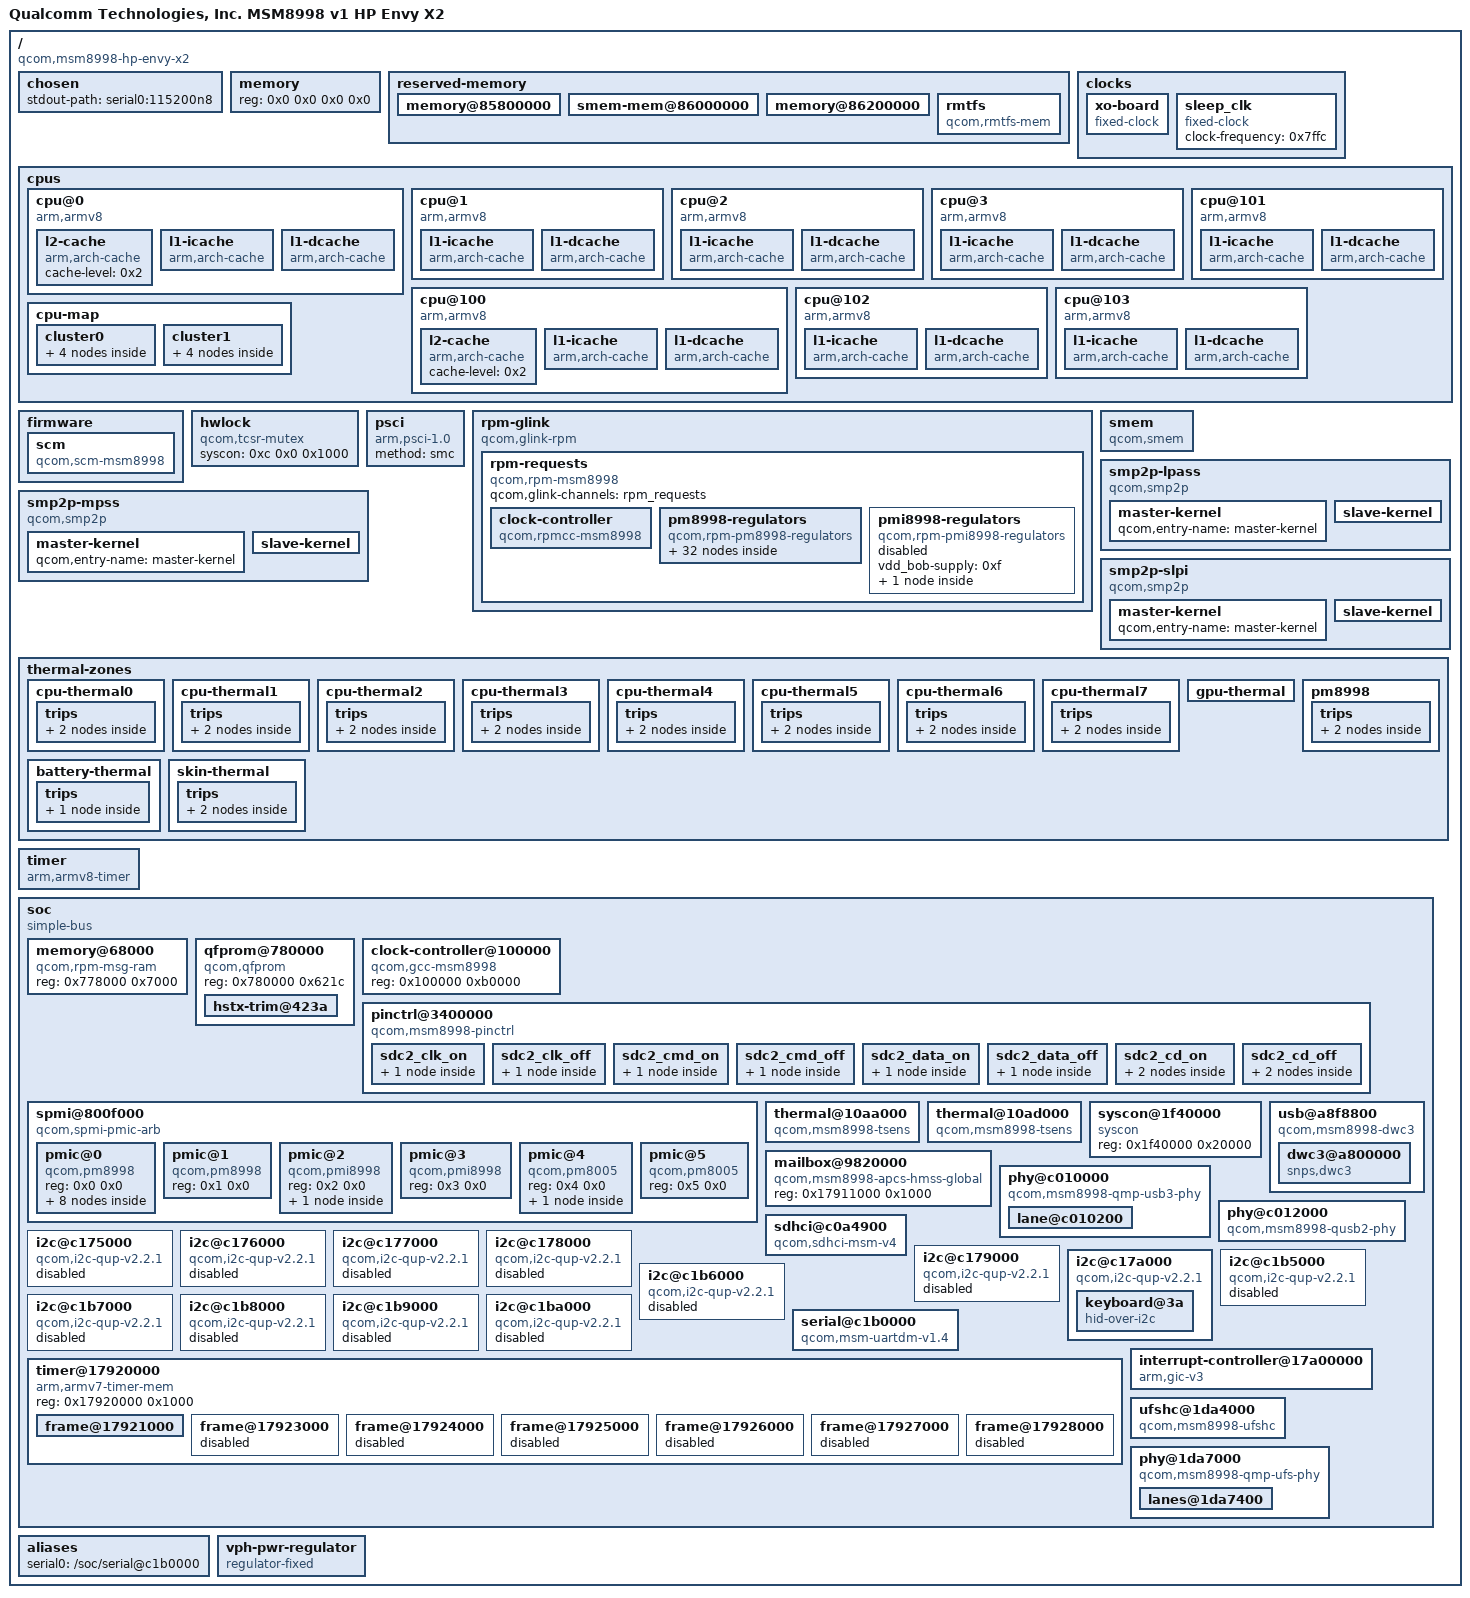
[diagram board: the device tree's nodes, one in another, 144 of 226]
/dts-v1/;

/ {
	interrupt-parent = <0x1>;
	qcom,msm-id = <0x124 0x0>;
	#address-cells = <0x2>;
	#size-cells = <0x2>;
	model = "Qualcomm Technologies, Inc. MSM8998 v1 HP Envy X2";
	compatible = "qcom,msm8998-hp-envy-x2";
	qcom,board-id = <0x8 0x0>;

	chosen {
		stdout-path = "serial0:115200n8";
	};

	memory {
		device_type = "memory";
		reg = <0x0 0x0 0x0 0x0>;
	};

	reserved-memory {
		#address-cells = <0x2>;
		#size-cells = <0x2>;
		ranges;

		memory@85800000 {
			reg = <0x0 0x85800000 0x0 0x800000>;
			no-map;
		};

		smem-mem@86000000 {
			reg = <0x0 0x86000000 0x0 0x200000>;
			no-map;
			phandle = <0x14>;
		};

		memory@86200000 {
			reg = <0x0 0x86200000 0x0 0x2600000>;
			no-map;
		};

		rmtfs {
			compatible = "qcom,rmtfs-mem";
			size = <0x0 0x200000>;
			alloc-ranges = <0x0 0xa0000000 0x0 0x2000000>;
			no-map;
			qcom,client-id = <0x1>;
			qcom,vmid = <0xf>;
		};
	};

	clocks {

		xo-board {
			compatible = "fixed-clock";
			#clock-cells = <0x0>;
			clock-frequency = <0x124f800>;
			clock-output-names = "xo_board";
			phandle = <0x21>;
		};

		sleep_clk {
			compatible = "fixed-clock";
			#clock-cells = <0x0>;
			clock-frequency = <0x7ffc>;
		};
	};

	cpus {
		#address-cells = <0x2>;
		#size-cells = <0x0>;

		cpu@0 {
			device_type = "cpu";
			compatible = "arm,armv8";
			reg = <0x0 0x0>;
			enable-method = "psci";
			efficiency = <0x400>;
			next-level-cache = <0x2>;
			phandle = <0x4>;

			l2-cache {
				compatible = "arm,arch-cache";
				cache-level = <0x2>;
				phandle = <0x2>;
			};

			l1-icache {
				compatible = "arm,arch-cache";
			};

			l1-dcache {
				compatible = "arm,arch-cache";
			};
		};

		cpu@1 {
			device_type = "cpu";
			compatible = "arm,armv8";
			reg = <0x0 0x1>;
			enable-method = "psci";
			efficiency = <0x400>;
			next-level-cache = <0x2>;
			phandle = <0x5>;

			l1-icache {
				compatible = "arm,arch-cache";
			};

			l1-dcache {
				compatible = "arm,arch-cache";
			};
		};

		cpu@2 {
			device_type = "cpu";
			compatible = "arm,armv8";
			reg = <0x0 0x2>;
			enable-method = "psci";
			efficiency = <0x400>;
			next-level-cache = <0x2>;
			phandle = <0x6>;

			l1-icache {
				compatible = "arm,arch-cache";
			};

			l1-dcache {
				compatible = "arm,arch-cache";
			};
		};

		cpu@3 {
			device_type = "cpu";
			compatible = "arm,armv8";
			reg = <0x0 0x3>;
			enable-method = "psci";
			efficiency = <0x400>;
			next-level-cache = <0x2>;
			phandle = <0x7>;

			l1-icache {
				compatible = "arm,arch-cache";
			};

			l1-dcache {
				compatible = "arm,arch-cache";
			};
		};

		cpu@100 {
			device_type = "cpu";
			compatible = "arm,armv8";
			reg = <0x0 0x100>;
			enable-method = "psci";
			efficiency = <0x600>;
			next-level-cache = <0x3>;
			phandle = <0x8>;

			l2-cache {
				compatible = "arm,arch-cache";
				cache-level = <0x2>;
				phandle = <0x3>;
			};

			l1-icache {
				compatible = "arm,arch-cache";
			};

			l1-dcache {
				compatible = "arm,arch-cache";
			};
		};

		cpu@101 {
			device_type = "cpu";
			compatible = "arm,armv8";
			reg = <0x0 0x101>;
			enable-method = "psci";
			efficiency = <0x600>;
			next-level-cache = <0x3>;
			phandle = <0x9>;

			l1-icache {
				compatible = "arm,arch-cache";
			};

			l1-dcache {
				compatible = "arm,arch-cache";
			};
		};

		cpu@102 {
			device_type = "cpu";
			compatible = "arm,armv8";
			reg = <0x0 0x102>;
			enable-method = "psci";
			efficiency = <0x600>;
			next-level-cache = <0x3>;
			phandle = <0xa>;

			l1-icache {
				compatible = "arm,arch-cache";
			};

			l1-dcache {
				compatible = "arm,arch-cache";
			};
		};

		cpu@103 {
			device_type = "cpu";
			compatible = "arm,armv8";
			reg = <0x0 0x103>;
			enable-method = "psci";
			efficiency = <0x600>;
			next-level-cache = <0x3>;
			phandle = <0xb>;

			l1-icache {
				compatible = "arm,arch-cache";
			};

			l1-dcache {
				compatible = "arm,arch-cache";
			};
		};

		cpu-map {

			cluster0 {

				core0 {
					cpu = <0x4>;
				};

				core1 {
					cpu = <0x5>;
				};

				core2 {
					cpu = <0x6>;
				};

				core3 {
					cpu = <0x7>;
				};
			};

			cluster1 {

				core0 {
					cpu = <0x8>;
				};

				core1 {
					cpu = <0x9>;
				};

				core2 {
					cpu = <0xa>;
				};

				core3 {
					cpu = <0xb>;
				};
			};
		};
	};

	firmware {

		scm {
			compatible = "qcom,scm-msm8998", "qcom,scm";
		};
	};

	hwlock {
		compatible = "qcom,tcsr-mutex";
		syscon = <0xc 0x0 0x1000>;
		#hwlock-cells = <0x1>;
		phandle = <0x15>;
	};

	psci {
		compatible = "arm,psci-1.0";
		method = "smc";
	};

	rpm-glink {
		compatible = "qcom,glink-rpm";
		interrupts = <0x0 0xa8 0x1>;
		qcom,rpm-msg-ram = <0xd>;
		mboxes = <0xe 0x0>;

		rpm-requests {
			compatible = "qcom,rpm-msm8998";
			qcom,glink-channels = "rpm_requests";

			clock-controller {
				compatible = "qcom,rpmcc-msm8998", "qcom,rpmcc";
				#clock-cells = <0x1>;
				phandle = <0x2e>;
			};

			pm8998-regulators {
				compatible = "qcom,rpm-pm8998-regulators";
				vdd_s1-supply = <0xf>;
				vdd_s2-supply = <0xf>;
				vdd_s3-supply = <0xf>;
				vdd_s4-supply = <0xf>;
				vdd_s5-supply = <0xf>;
				vdd_s6-supply = <0xf>;
				vdd_s7-supply = <0xf>;
				vdd_s8-supply = <0xf>;
				vdd_s9-supply = <0xf>;
				vdd_s10-supply = <0xf>;
				vdd_s11-supply = <0xf>;
				vdd_s12-supply = <0xf>;
				vdd_s13-supply = <0xf>;
				vdd_l1_l27-supply = <0x10>;
				vdd_l2_l8_l17-supply = <0x11>;
				vdd_l3_l11-supply = <0x10>;
				vdd_l4_l5-supply = <0x10>;
				vdd_l6-supply = <0x12>;
				vdd_l7_l12_l14_l15-supply = <0x12>;
				vdd_l9-supply = <0xf>;
				vdd_l10_l23_l25-supply = <0xf>;
				vdd_l13_l19_l21-supply = <0xf>;
				vdd_l16_l28-supply = <0xf>;
				vdd_l18_l22-supply = <0xf>;
				vdd_l20_l24-supply = <0xf>;
				vdd_l26-supply = <0x11>;
				vdd_lvs1_lvs2-supply = <0x13>;
				status = "okay";

				s3 {
					regulator-min-microvolt = <0x14a140>;
					regulator-max-microvolt = <0x14a140>;
					phandle = <0x11>;
				};

				s4 {
					regulator-min-microvolt = <0x1b7740>;
					regulator-max-microvolt = <0x1b7740>;
					regulator-allow-set-load;
					phandle = <0x13>;
				};

				s5 {
					regulator-min-microvolt = <0x1d0d80>;
					regulator-max-microvolt = <0x1f20c0>;
					phandle = <0x12>;
				};

				s7 {
					regulator-min-microvolt = <0xdbba0>;
					regulator-max-microvolt = <0xfafa0>;
					phandle = <0x10>;
				};

				l1 {
					regulator-min-microvolt = <0xd6d80>;
					regulator-max-microvolt = <0xd6d80>;
					phandle = <0x1c>;
				};

				l2 {
					regulator-min-microvolt = <0x124f80>;
					regulator-max-microvolt = <0x124f80>;
					phandle = <0x1d>;
				};

				l3 {
					regulator-min-microvolt = <0xf4240>;
					regulator-max-microvolt = <0xf4240>;
				};

				l5 {
					regulator-min-microvolt = <0xc3500>;
					regulator-max-microvolt = <0xc3500>;
				};

				l6 {
					regulator-min-microvolt = <0x1b9680>;
					regulator-max-microvolt = <0x1b9680>;
				};

				l7 {
					regulator-min-microvolt = <0x1b7740>;
					regulator-max-microvolt = <0x1b7740>;
				};

				l8 {
					regulator-min-microvolt = <0x124f80>;
					regulator-max-microvolt = <0x124f80>;
				};

				l9 {
					regulator-min-microvolt = <0x1b9680>;
					regulator-max-microvolt = <0x2d2a80>;
				};

				l10 {
					regulator-min-microvolt = <0x1b9680>;
					regulator-max-microvolt = <0x2d2a80>;
				};

				l11 {
					regulator-min-microvolt = <0xf4240>;
					regulator-max-microvolt = <0xf4240>;
				};

				l12 {
					regulator-min-microvolt = <0x1b7740>;
					regulator-max-microvolt = <0x1b7740>;
					phandle = <0x1f>;
				};

				l13 {
					regulator-min-microvolt = <0x1b9680>;
					regulator-max-microvolt = <0x2d2a80>;
					phandle = <0x24>;
				};

				l14 {
					regulator-min-microvolt = <0x1cafc0>;
					regulator-max-microvolt = <0x1cafc0>;
				};

				l15 {
					regulator-min-microvolt = <0x1b7740>;
					regulator-max-microvolt = <0x1b7740>;
				};

				l16 {
					regulator-min-microvolt = <0x294280>;
					regulator-max-microvolt = <0x294280>;
				};

				l17 {
					regulator-min-microvolt = <0x13e5c0>;
					regulator-max-microvolt = <0x13e5c0>;
				};

				l18 {
					regulator-min-microvolt = <0x294280>;
					regulator-max-microvolt = <0x294280>;
				};

				l19 {
					regulator-min-microvolt = <0x2de600>;
					regulator-max-microvolt = <0x2de600>;
				};

				l20 {
					regulator-min-microvolt = <0x2d2a80>;
					regulator-max-microvolt = <0x2d2a80>;
					regulator-allow-set-load;
					phandle = <0x2f>;
				};

				l21 {
					regulator-min-microvolt = <0x2d2a80>;
					regulator-max-microvolt = <0x2d2a80>;
					regulator-allow-set-load;
					regulator-system-load = <0xc3500>;
					phandle = <0x23>;
				};

				l22 {
					regulator-min-microvolt = <0x2bb380>;
					regulator-max-microvolt = <0x2bb380>;
				};

				l23 {
					regulator-min-microvolt = <0x328980>;
					regulator-max-microvolt = <0x328980>;
				};

				l24 {
					regulator-min-microvolt = <0x2f1e80>;
					regulator-max-microvolt = <0x2f1e80>;
					phandle = <0x20>;
				};

				l25 {
					regulator-min-microvolt = <0x2f5d00>;
					regulator-max-microvolt = <0x328980>;
				};

				l26 {
					regulator-min-microvolt = <0x124f80>;
					regulator-max-microvolt = <0x124f80>;
					regulator-allow-set-load;
					phandle = <0x30>;
				};

				l28 {
					regulator-min-microvolt = <0x2de600>;
					regulator-max-microvolt = <0x2de600>;
				};

				lvs1 {
					regulator-min-microvolt = <0x1b7740>;
					regulator-max-microvolt = <0x1b7740>;
				};

				lvs2 {
					regulator-min-microvolt = <0x1b7740>;
					regulator-max-microvolt = <0x1b7740>;
				};
			};

			pmi8998-regulators {
				compatible = "qcom,rpm-pmi8998-regulators";
				vdd_bob-supply = <0xf>;
				status = "disabled";

				bob {
					regulator-min-microvolt = <0x328980>;
					regulator-max-microvolt = <0x36ee80>;
				};
			};
		};
	};

	smem {
		compatible = "qcom,smem";
		memory-region = <0x14>;
		hwlocks = <0x15 0x3>;
	};

	smp2p-lpass {
		compatible = "qcom,smp2p";
		qcom,smem = <0x1bb 0x1ad>;
		interrupts = <0x0 0x9e 0x1>;
		mboxes = <0xe 0xa>;
		qcom,local-pid = <0x0>;
		qcom,remote-pid = <0x2>;

		master-kernel {
			qcom,entry-name = "master-kernel";
			#qcom,smem-state-cells = <0x1>;
		};

		slave-kernel {
			qcom,entry-name = "slave-kernel";
			interrupt-controller;
			#interrupt-cells = <0x2>;
		};
	};

	smp2p-mpss {
		compatible = "qcom,smp2p";
		qcom,smem = <0x1b3 0x1ac>;
		interrupts = <0x0 0x1c3 0x1>;
		mboxes = <0xe 0xe>;
		qcom,local-pid = <0x0>;
		qcom,remote-pid = <0x1>;

		master-kernel {
			qcom,entry-name = "master-kernel";
			#qcom,smem-state-cells = <0x1>;
		};

		slave-kernel {
			qcom,entry-name = "slave-kernel";
			interrupt-controller;
			#interrupt-cells = <0x2>;
		};
	};

	smp2p-slpi {
		compatible = "qcom,smp2p";
		qcom,smem = <0x1e1 0x1ae>;
		interrupts = <0x0 0xb2 0x1>;
		mboxes = <0xe 0x1a>;
		qcom,local-pid = <0x0>;
		qcom,remote-pid = <0x3>;

		master-kernel {
			qcom,entry-name = "master-kernel";
			#qcom,smem-state-cells = <0x1>;
		};

		slave-kernel {
			qcom,entry-name = "slave-kernel";
			interrupt-controller;
			#interrupt-cells = <0x2>;
		};
	};

	thermal-zones {

		cpu-thermal0 {
			polling-delay-passive = <0xfa>;
			polling-delay = <0x3e8>;
			thermal-sensors = <0x16 0x6>;

			trips {

				trip0 {
					temperature = <0x124f8>;
					hysteresis = <0x7d0>;
					type = "passive";
				};

				trip1 {
					temperature = <0x1adb0>;
					hysteresis = <0x7d0>;
					type = "critical";
				};
			};
		};

		cpu-thermal1 {
			polling-delay-passive = <0xfa>;
			polling-delay = <0x3e8>;
			thermal-sensors = <0x16 0x7>;

			trips {

				trip0 {
					temperature = <0x124f8>;
					hysteresis = <0x7d0>;
					type = "passive";
				};

				trip1 {
					temperature = <0x1adb0>;
					hysteresis = <0x7d0>;
					type = "critical";
				};
			};
		};

		cpu-thermal2 {
			polling-delay-passive = <0xfa>;
			polling-delay = <0x3e8>;
			thermal-sensors = <0x16 0x8>;

			trips {

				trip0 {
					temperature = <0x124f8>;
					hysteresis = <0x7d0>;
					type = "passive";
				};

				trip1 {
					temperature = <0x1adb0>;
					hysteresis = <0x7d0>;
					type = "critical";
				};
			};
		};

		cpu-thermal3 {
			polling-delay-passive = <0xfa>;
			polling-delay = <0x3e8>;
			thermal-sensors = <0x16 0x9>;

			trips {

				trip0 {
					temperature = <0x124f8>;
					hysteresis = <0x7d0>;
					type = "passive";
				};

				trip1 {
					temperature = <0x1adb0>;
					hysteresis = <0x7d0>;
					type = "critical";
				};
			};
		};

		cpu-thermal4 {
			polling-delay-passive = <0xfa>;
			polling-delay = <0x3e8>;
			thermal-sensors = <0x16 0xa>;

			trips {

				trip0 {
					temperature = <0x124f8>;
					hysteresis = <0x7d0>;
					type = "passive";
				};

				trip1 {
					temperature = <0x1adb0>;
					hysteresis = <0x7d0>;
					type = "critical";
				};
			};
		};

		cpu-thermal5 {
			polling-delay-passive = <0xfa>;
			polling-delay = <0x3e8>;
			thermal-sensors = <0x16 0xb>;

			trips {

				trip0 {
					temperature = <0x124f8>;
					hysteresis = <0x7d0>;
					type = "passive";
				};

				trip1 {
					temperature = <0x1adb0>;
					hysteresis = <0x7d0>;
					type = "critical";
				};
			};
		};

		cpu-thermal6 {
			polling-delay-passive = <0xfa>;
			polling-delay = <0x3e8>;
			thermal-sensors = <0x17 0x0>;

			trips {

				trip0 {
					temperature = <0x124f8>;
					hysteresis = <0x7d0>;
					type = "passive";
				};

				trip1 {
					temperature = <0x1adb0>;
					hysteresis = <0x7d0>;
					type = "critical";
				};
			};
		};

		cpu-thermal7 {
			polling-delay-passive = <0xfa>;
			polling-delay = <0x3e8>;
			thermal-sensors = <0x17 0x1>;

			trips {

				trip0 {
					temperature = <0x124f8>;
					hysteresis = <0x7d0>;
					type = "passive";
				};

				trip1 {
					temperature = <0x1adb0>;
					hysteresis = <0x7d0>;
					type = "critical";
				};
			};
		};

		gpu-thermal {
			polling-delay-passive = <0xfa>;
			polling-delay = <0x3e8>;
			thermal-sensors = <0x17 0x3>;
		};

		pm8998 {
			polling-delay-passive = <0xfa>;
			polling-delay = <0x3e8>;
			thermal-sensors = <0x18>;

			trips {

				pm8998-alert0 {
					temperature = <0x19a28>;
					hysteresis = <0x7d0>;
					type = "passive";
				};

				pm8998-crit {
					temperature = <0x1e848>;
					hysteresis = <0x7d0>;
					type = "critical";
				};
			};
		};

		battery-thermal {
			polling-delay-passive = <0xfa>;
			polling-delay = <0x3e8>;
			thermal-sensors = <0x16 0x0>;

			trips {

				trip0 {
					temperature = <0xea60>;
					hysteresis = <0x7d0>;
					type = "critical";
				};
			};
		};

		skin-thermal {
			polling-delay-passive = <0xfa>;
			polling-delay = <0x3e8>;
			thermal-sensors = <0x17 0x5>;

			trips {

				trip0 {
					temperature = <0xabe0>;
					hysteresis = <0x7d0>;
					type = "passive";
				};

				trip1 {
					temperature = <0x11170>;
					hysteresis = <0x7d0>;
					type = "critical";
				};
			};
		};
	};

	timer {
		compatible = "arm,armv8-timer";
		interrupts = <0x1 0x1 0x8 0x1 0x2 0x8 0x1 0x3 0x8 0x1 0x0 0x8>;
	};

	soc {
		#address-cells = <0x1>;
		#size-cells = <0x1>;
		ranges = <0x0 0x0 0x0 0xffffffff>;
		compatible = "simple-bus";

		memory@68000 {
			compatible = "qcom,rpm-msg-ram";
			reg = <0x778000 0x7000>;
			phandle = <0xd>;
		};

		qfprom@780000 {
			compatible = "qcom,qfprom";
			reg = <0x780000 0x621c>;
			#address-cells = <0x1>;
			#size-cells = <0x1>;

			hstx-trim@423a {
				reg = <0x423a 0x1>;
				bits = <0x0 0x4>;
				phandle = <0x1e>;
			};
		};

		clock-controller@100000 {
			compatible = "qcom,gcc-msm8998";
			#clock-cells = <0x1>;
			#reset-cells = <0x1>;
			#power-domain-cells = <0x1>;
			reg = <0x100000 0xb0000>;
			phandle = <0x19>;
		};

		pinctrl@3400000 {
			compatible = "qcom,msm8998-pinctrl";
			reg = <0x3400000 0xc00000>;
			interrupts = <0x0 0xd0 0x4>;
			gpio-controller;
			#gpio-cells = <0x2>;
			interrupt-controller;
			#interrupt-cells = <0x2>;
			gpio-reserved-ranges = <0x0 0x4 0x51 0x4>;
			phandle = <0x22>;

			sdc2_clk_on {
				phandle = <0x25>;

				config {
					pins = "sdc2_clk";
					bias-disable;
					drive-strength = <0x10>;
				};
			};

			sdc2_clk_off {
				phandle = <0x29>;

				config {
					pins = "sdc2_clk";
					bias-disable;
					drive-strength = <0x2>;
				};
			};

			sdc2_cmd_on {
				phandle = <0x26>;

				config {
					pins = "sdc2_cmd";
					bias-pull-up;
					drive-strength = <0xa>;
				};
			};

			sdc2_cmd_off {
				phandle = <0x2a>;

				config {
					pins = "sdc2_cmd";
					bias-pull-up;
					drive-strength = <0x2>;
				};
			};

			sdc2_data_on {
				phandle = <0x27>;

				config {
					pins = "sdc2_data";
					bias-pull-up;
					drive-strength = <0xa>;
				};
			};

			sdc2_data_off {
				phandle = <0x2b>;

				config {
					pins = "sdc2_data";
					bias-pull-up;
					drive-strength = <0x2>;
				};
			};

			sdc2_cd_on {
				phandle = <0x28>;

				mux {
					pins = "gpio95";
					function = "gpio";
				};

				config {
					pins = "gpio95";
					bias-pull-up;
					drive-strength = <0x2>;
				};
			};

			sdc2_cd_off {
				phandle = <0x2c>;

				mux {
					pins = "gpio95";
					function = "gpio";
				};

				config {
					pins = "gpio95";
					bias-pull-up;
					drive-strength = <0x2>;
				};
			};
		};

		spmi@800f000 {
			compatible = "qcom,spmi-pmic-arb";
			reg = <0x800f000 0x1000 0x8400000 0x1000000 0x9400000 0x1000000 0xa400000 0x220000 0x800a000 0x3000>;
			reg-names = "core", "chnls", "obsrvr", "intr", "cnfg";
			interrupt-names = "periph_irq";
			interrupts = <0x0 0x146 0x4>;
			qcom,ee = <0x0>;
			qcom,channel = <0x0>;
			#address-cells = <0x2>;
			#size-cells = <0x0>;
			interrupt-controller;
			#interrupt-cells = <0x4>;
			cell-index = <0x0>;

			pmic@0 {
				compatible = "qcom,pm8998", "qcom,spmi-pmic";
				reg = <0x0 0x0>;
				#address-cells = <0x1>;
				#size-cells = <0x0>;

				pon@800 {
					compatible = "qcom,pm8916-pon";
					reg = <0x800>;
					mode-bootloader = <0x2>;
					mode-recovery = <0x1>;

					pwrkey {
						compatible = "qcom,pm8941-pwrkey";
						interrupts = <0x0 0x8 0x0 0x3>;
						debounce = <0x3d09>;
						bias-pull-up;
						linux,code = <0x74>;
					};
				};

				temp-alarm@2400 {
					compatible = "qcom,spmi-temp-alarm";
					reg = <0x2400>;
					interrupts = <0x0 0x24 0x0 0x1>;
					#thermal-sensor-cells = <0x0>;
					phandle = <0x18>;
				};

				coincell@2800 {
					compatible = "qcom,pm8941-coincell";
					reg = <0x2800>;
					status = "disabled";
				};

				adc@3100 {
					compatible = "qcom,spmi-adc-rev2";
					reg = <0x3100>;
					interrupts = <0x0 0x31 0x0 0x1>;
					#address-cells = <0x1>;
					#size-cells = <0x0>;
					#io-channel-cells = <0x1>;

					adc-chan@0x06 {
						reg = <0x6>;
						label = "die_temp";
					};
				};

				rtc@6000 {
					compatible = "qcom,pm8941-rtc";
					reg = <0x6000 0x6100>;
					reg-names = "rtc", "alarm";
					interrupts = <0x0 0x61 0x1 0x1>;
				};

				gpios@c000 {
					compatible = "qcom,pm8998-gpio", "qcom,spmi-gpio";
					reg = <0xc000>;
					gpio-controller;
					#gpio-cells = <0x2>;
					interrupt-controller;
					#interrupt-cells = <0x2>;
				};
			};

			pmic@1 {
				compatible = "qcom,pm8998", "qcom,spmi-pmic";
				reg = <0x1 0x0>;
				#address-cells = <0x1>;
				#size-cells = <0x0>;
			};

			pmic@2 {
				compatible = "qcom,pmi8998", "qcom,spmi-pmic";
				reg = <0x2 0x0>;
				#address-cells = <0x1>;
				#size-cells = <0x0>;

				gpios@c000 {
					compatible = "qcom,pmi8998-gpio", "qcom,spmi-gpio";
					reg = <0xc000>;
					gpio-controller;
					#gpio-cells = <0x2>;
					interrupt-controller;
					#interrupt-cells = <0x2>;
				};
			};

			pmic@3 {
				compatible = "qcom,pmi8998", "qcom,spmi-pmic";
				reg = <0x3 0x0>;
				#address-cells = <0x1>;
				#size-cells = <0x0>;
			};

			pmic@4 {
				compatible = "qcom,pm8005", "qcom,spmi-pmic";
				reg = <0x4 0x0>;
				#address-cells = <0x1>;
				#size-cells = <0x0>;

				gpios@c000 {
					compatible = "qcom,pm8005-gpio", "qcom,spmi-gpio";
					reg = <0xc000>;
					gpio-controller;
					#gpio-cells = <0x2>;
					interrupt-controller;
					#interrupt-cells = <0x2>;
				};
			};

			pmic@5 {
				compatible = "qcom,pm8005", "qcom,spmi-pmic";
				reg = <0x5 0x0>;
				#address-cells = <0x1>;
				#size-cells = <0x0>;
			};
		};

		thermal@10aa000 {
			compatible = "qcom,msm8998-tsens", "qcom,tsens-v2";
			reg = <0x10aa000 0x2000>;
			#qcom,sensors = <0xc>;
			#thermal-sensor-cells = <0x1>;
			phandle = <0x16>;
		};

		thermal@10ad000 {
			compatible = "qcom,msm8998-tsens", "qcom,tsens-v2";
			reg = <0x10ad000 0x2000>;
			#qcom,sensors = <0x8>;
			#thermal-sensor-cells = <0x1>;
			phandle = <0x17>;
		};

		syscon@1f40000 {
			compatible = "syscon";
			reg = <0x1f40000 0x20000>;
			phandle = <0xc>;
		};

		mailbox@9820000 {
			compatible = "qcom,msm8998-apcs-hmss-global";
			reg = <0x17911000 0x1000>;
			#mbox-cells = <0x1>;
			phandle = <0xe>;
		};

		usb@a8f8800 {
			compatible = "qcom,msm8998-dwc3", "qcom,dwc3";
			reg = <0xa8f8800 0x400>;
			status = "okay";
			#address-cells = <0x1>;
			#size-cells = <0x1>;
			ranges;
			clocks = <0x19 0x47 0x19 0x74 0x19 0x20 0x19 0x75 0x19 0x76>;
			clock-names = "cfg_noc", "core", "iface", "mock_utmi", "sleep";
			assigned-clocks = <0x19 0x75 0x19 0x74>;
			assigned-clock-rates = <0x124f800 0x7270e00>;
			interrupts = <0x0 0x15b 0x4 0x0 0xf3 0x4>;
			interrupt-names = "hs_phy_irq", "ss_phy_irq";
			power-domains = <0x19 0x2>;
			resets = <0x19 0x12>;

			dwc3@a800000 {
				compatible = "snps,dwc3";
				reg = <0xa800000 0xcd00>;
				interrupts = <0x0 0x83 0x4>;
				snps,dis_u2_susphy_quirk;
				snps,dis_enblslpm_quirk;
				phys = <0x1a 0x1b>;
				phy-names = "usb2-phy", "usb3-phy";
				snps,has-lpm-erratum;
				snps,hird-threshold = [10];
				dr_mode = "host";
			};
		};

		phy@c010000 {
			compatible = "qcom,msm8998-qmp-usb3-phy";
			reg = <0xc010000 0x18c>;
			status = "okay";
			#clock-cells = <0x1>;
			#address-cells = <0x1>;
			#size-cells = <0x1>;
			ranges;
			clocks = <0x19 0x77 0x19 0x79 0x19 0xa6>;
			clock-names = "aux", "cfg_ahb", "ref";
			resets = <0x19 0x45 0x19 0x46>;
			reset-names = "phy", "common";
			vdda-phy-supply = <0x1c>;
			vdda-pll-supply = <0x1d>;

			lane@c010200 {
				reg = <0xc010200 0x128 0xc010400 0x200 0xc010c00 0x20c 0xc010600 0x128 0xc010800 0x200>;
				#phy-cells = <0x0>;
				clocks = <0x19 0x78>;
				clock-names = "pipe0";
				clock-output-names = "usb3_phy_pipe_clk_src";
				phandle = <0x1b>;
			};
		};

		phy@c012000 {
			compatible = "qcom,msm8998-qusb2-phy";
			reg = <0xc012000 0x2a8>;
			status = "okay";
			#phy-cells = <0x0>;
			clocks = <0x19 0x79 0x19 0xaa>;
			clock-names = "cfg_ahb", "ref";
			resets = <0x19 0x6a>;
			nvmem-cells = <0x1e>;
			vdda-pll-supply = <0x1f>;
			vdda-phy-dpdm-supply = <0x20>;
			phandle = <0x1a>;
		};

		sdhci@c0a4900 {
			compatible = "qcom,sdhci-msm-v4";
			reg = <0xc0a4900 0x314 0xc0a4000 0x800>;
			reg-names = "hc_mem", "core_mem";
			interrupts = <0x0 0x7d 0x4 0x0 0xdd 0x4>;
			interrupt-names = "hc_irq", "pwr_irq";
			clock-names = "iface", "core", "xo";
			clocks = <0x19 0x65 0x19 0x66 0x21>;
			bus-width = <0x4>;
			status = "okay";
			cd-gpios = <0x22 0x5f 0x1>;
			vmmc-supply = <0x23>;
			vqmmc-supply = <0x24>;
			pinctrl-names = "default", "sleep";
			pinctrl-0 = <0x25 0x26 0x27 0x28>;
			pinctrl-1 = <0x29 0x2a 0x2b 0x2c>;
		};

		i2c@c175000 {
			compatible = "qcom,i2c-qup-v2.2.1";
			reg = <0xc175000 0x600>;
			interrupts = <0x0 0x5f 0x4>;
			clocks = <0x19 0x26 0x19 0x25>;
			clock-names = "core", "iface";
			clock-frequency = <0x61a80>;
			status = "disabled";
			#address-cells = <0x1>;
			#size-cells = <0x0>;
		};

		i2c@c176000 {
			compatible = "qcom,i2c-qup-v2.2.1";
			reg = <0xc176000 0x600>;
			interrupts = <0x0 0x60 0x4>;
			clocks = <0x19 0x28 0x19 0x25>;
			clock-names = "core", "iface";
			clock-frequency = <0x61a80>;
			status = "disabled";
			#address-cells = <0x1>;
			#size-cells = <0x0>;
		};

		i2c@c177000 {
			compatible = "qcom,i2c-qup-v2.2.1";
			reg = <0xc177000 0x600>;
			interrupts = <0x0 0x61 0x4>;
			clocks = <0x19 0x2a 0x19 0x25>;
			clock-names = "core", "iface";
			clock-frequency = <0x61a80>;
			status = "disabled";
			#address-cells = <0x1>;
			#size-cells = <0x0>;
		};

		i2c@c178000 {
			compatible = "qcom,i2c-qup-v2.2.1";
			reg = <0xc178000 0x600>;
			interrupts = <0x0 0x62 0x4>;
			clocks = <0x19 0x2c 0x19 0x25>;
			clock-names = "core", "iface";
			clock-frequency = <0x61a80>;
			status = "disabled";
			#address-cells = <0x1>;
			#size-cells = <0x0>;
		};

		i2c@c179000 {
			compatible = "qcom,i2c-qup-v2.2.1";
			reg = <0xc179000 0x600>;
			interrupts = <0x0 0x63 0x4>;
			clocks = <0x19 0x2e 0x19 0x25>;
			clock-names = "core", "iface";
			clock-frequency = <0x61a80>;
			status = "disabled";
			#address-cells = <0x1>;
			#size-cells = <0x0>;
		};

		i2c@c17a000 {
			compatible = "qcom,i2c-qup-v2.2.1";
			reg = <0xc17a000 0x600>;
			interrupts = <0x0 0x64 0x4>;
			clocks = <0x19 0x30 0x19 0x25>;
			clock-names = "core", "iface";
			clock-frequency = <0x61a80>;
			status = "okay";
			#address-cells = <0x1>;
			#size-cells = <0x0>;

			keyboard@3a {
				compatible = "hid-over-i2c";
				interrupt-parent = <0x22>;
				interrupts = <0x79 0x8>;
				reg = <0x3a>;
				hid-descr-addr = <0x1>;
			};
		};

		i2c@c1b5000 {
			compatible = "qcom,i2c-qup-v2.2.1";
			reg = <0xc1b5000 0x600>;
			interrupts = <0x0 0x65 0x4>;
			clocks = <0x19 0x37 0x19 0x36>;
			clock-names = "core", "iface";
			clock-frequency = <0x61a80>;
			status = "disabled";
			#address-cells = <0x1>;
			#size-cells = <0x0>;
		};

		i2c@c1b6000 {
			compatible = "qcom,i2c-qup-v2.2.1";
			reg = <0xc1b6000 0x600>;
			interrupts = <0x0 0x66 0x4>;
			clocks = <0x19 0x39 0x19 0x36>;
			clock-names = "core", "iface";
			clock-frequency = <0x61a80>;
			status = "disabled";
			#address-cells = <0x1>;
			#size-cells = <0x0>;
		};

		i2c@c1b7000 {
			compatible = "qcom,i2c-qup-v2.2.1";
			reg = <0xc1b7000 0x600>;
			interrupts = <0x0 0x67 0x4>;
			clocks = <0x19 0x3b 0x19 0x36>;
			clock-names = "core", "iface";
			clock-frequency = <0x61a80>;
			status = "disabled";
			#address-cells = <0x1>;
			#size-cells = <0x0>;
		};

		i2c@c1b8000 {
			compatible = "qcom,i2c-qup-v2.2.1";
			reg = <0xc1b8000 0x600>;
			interrupts = <0x0 0x68 0x4>;
			clocks = <0x19 0x3d 0x19 0x36>;
			clock-names = "core", "iface";
			clock-frequency = <0x61a80>;
			status = "disabled";
			#address-cells = <0x1>;
			#size-cells = <0x0>;
		};

		i2c@c1b9000 {
			compatible = "qcom,i2c-qup-v2.2.1";
			reg = <0xc1b9000 0x600>;
			interrupts = <0x0 0x69 0x4>;
			clocks = <0x19 0x3f 0x19 0x36>;
			clock-names = "core", "iface";
			clock-frequency = <0x61a80>;
			status = "disabled";
			#address-cells = <0x1>;
			#size-cells = <0x0>;
		};

		i2c@c1ba000 {
			compatible = "qcom,i2c-qup-v2.2.1";
			reg = <0xc175000 0x600>;
			interrupts = <0x0 0x6a 0x4>;
			clocks = <0x19 0x41 0x19 0x36>;
			clock-names = "core", "iface";
			clock-frequency = <0x61a80>;
			status = "disabled";
			#address-cells = <0x1>;
			#size-cells = <0x0>;
		};

		serial@c1b0000 {
			compatible = "qcom,msm-uartdm-v1.4", "qcom,msm-uartdm";
			reg = <0xc1b0000 0x1000>;
			interrupts = <0x0 0x72 0x4>;
			clocks = <0x19 0x45 0x19 0x36>;
			clock-names = "core", "iface";
			status = "okay";
		};

		timer@17920000 {
			#address-cells = <0x1>;
			#size-cells = <0x1>;
			ranges;
			compatible = "arm,armv7-timer-mem";
			reg = <0x17920000 0x1000>;

			frame@17921000 {
				frame-number = <0x0>;
				interrupts = <0x0 0x8 0x4 0x0 0x7 0x4>;
				reg = <0x17921000 0x1000 0x17922000 0x1000>;
			};

			frame@17923000 {
				frame-number = <0x1>;
				interrupts = <0x0 0x9 0x4>;
				reg = <0x17923000 0x1000>;
				status = "disabled";
			};

			frame@17924000 {
				frame-number = <0x2>;
				interrupts = <0x0 0xa 0x4>;
				reg = <0x17924000 0x1000>;
				status = "disabled";
			};

			frame@17925000 {
				frame-number = <0x3>;
				interrupts = <0x0 0xb 0x4>;
				reg = <0x17925000 0x1000>;
				status = "disabled";
			};

			frame@17926000 {
				frame-number = <0x4>;
				interrupts = <0x0 0xc 0x4>;
				reg = <0x17926000 0x1000>;
				status = "disabled";
			};

			frame@17927000 {
				frame-number = <0x5>;
				interrupts = <0x0 0xd 0x4>;
				reg = <0x17927000 0x1000>;
				status = "disabled";
			};

			frame@17928000 {
				frame-number = <0x6>;
				interrupts = <0x0 0xe 0x4>;
				reg = <0x17928000 0x1000>;
				status = "disabled";
			};
		};

		interrupt-controller@17a00000 {
			compatible = "arm,gic-v3";
			reg = <0x17a00000 0x10000 0x17b00000 0x100000>;
			#interrupt-cells = <0x3>;
			#address-cells = <0x1>;
			#size-cells = <0x1>;
			ranges;
			interrupt-controller;
			#redistributor-regions = <0x1>;
			redistributor-stride = <0x0 0x20000>;
			interrupts = <0x1 0x9 0x4>;
			phandle = <0x1>;
		};

		ufshc@1da4000 {
			compatible = "qcom,msm8998-ufshc", "qcom,ufshc", "jedec,ufs-2.0";
			reg = <0x1da4000 0x2500>;
			interrupts = <0x0 0x109 0x4>;
			phys = <0x2d>;
			phy-names = "ufsphy";
			lanes-per-direction = <0x2>;
			power-domains = <0x19 0x1>;
			clock-names = "core_clk", "bus_aggr_clk", "iface_clk", "core_clk_unipro", "ref_clk", "tx_lane0_sync_clk", "rx_lane0_sync_clk", "rx_lane1_sync_clk";
			clocks = <0x19 0x6d 0x19 0x1f 0x19 0x6c 0x19 0x73 0x2e 0x50 0x19 0x72 0x19 0x70 0x19 0x71>;
			freq-table-hz = <0x2faf080 0xbebc200 0x0 0x0 0x0 0x0 0x23c3460 0x8f0d180 0x0 0x0 0x0 0x0 0x0 0x0 0x0 0x0>;
			resets = <0x19 0x11>;
			reset-names = "rst";
			vcc-supply = <0x2f>;
			vccq-supply = <0x30>;
			vccq2-supply = <0x13>;
			vcc-max-microamp = <0xb71b0>;
			vccq-max-microamp = <0x88b80>;
			vccq2-max-microamp = <0xb71b0>;
		};

		phy@1da7000 {
			compatible = "qcom,msm8998-qmp-ufs-phy";
			reg = <0x1da7000 0x18c>;
			#address-cells = <0x1>;
			#size-cells = <0x1>;
			ranges;
			clock-names = "ref", "ref_aux";
			clocks = <0x19 0xa8 0x19 0x6f>;
			vdda-phy-supply = <0x1c>;
			vdda-pll-supply = <0x1d>;
			vddp-ref-clk-supply = <0x30>;
			vdda-phy-max-microamp = <0xc8c8>;
			vdda-pll-max-microamp = <0x3908>;
			vddp-ref-clk-max-microamp = <0x64>;
			vddp-ref-clk-always-on;

			lanes@1da7400 {
				reg = <0x1da7400 0x128 0x1da7600 0x1fc 0x1da7c00 0x1dc 0x1da7800 0x128 0x1da7a00 0x1fc>;
				#phy-cells = <0x0>;
				phandle = <0x2d>;
			};
		};
	};

	aliases {
		serial0 = "/soc/serial@c1b0000";
	};

	vph-pwr-regulator {
		compatible = "regulator-fixed";
		regulator-name = "vph_pwr";
		regulator-always-on;
		regulator-boot-on;
		phandle = <0xf>;
	};
};
